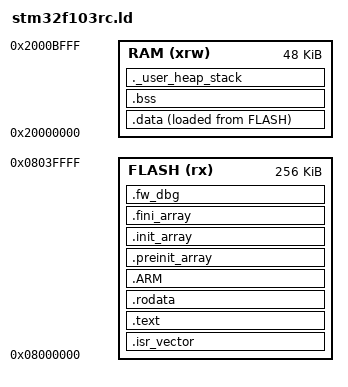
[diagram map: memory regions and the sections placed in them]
/*
 *
 * Automatically generated file
 * PlatformIO default linker script template for STM32 F1/F2/F3/F4/F7/L0/L1/L4
 *
 */

/* Entry Point */
ENTRY(Reset_Handler)

/* Highest address of the user mode stack */ 
_estack = 0x2000c000;    /* end of RAM */
/* Generate a link error if heap and stack don't fit into RAM */
_Min_Heap_Size = 0x8400;      /* required amount of heap  */
_Min_Stack_Size = 0x1600;     /* required amount of stack */

__stack_limit = _estack - _Min_Stack_Size;  /* end of stack */

/* Specify the memory areas */
MEMORY
{
    RAM (xrw)      : ORIGIN = 0x20000000, LENGTH = 49152
    FLASH (rx)      : ORIGIN = 0x8000000, LENGTH = 256K
}

/* Define output sections */
SECTIONS
{
  /* The startup code goes first into FLASH */
  .isr_vector :
  {
    . = ALIGN(4);
    KEEP(*(.isr_vector)) /* Startup code */
    . = ALIGN(4);
  } >FLASH

  /* The program code and other data goes into FLASH */
  .text :
  {
    . = ALIGN(4);
    *(.text)           /* .text sections (code) */
    *(.text*)          /* .text* sections (code) */
    *(.glue_7)         /* glue arm to thumb code */
    *(.glue_7t)        /* glue thumb to arm code */
    *(.eh_frame)

    KEEP (*(.init))
    KEEP (*(.fini))

    . = ALIGN(4);
    _etext = .;        /* define a global symbols at end of code */
  } >FLASH

  /* Constant data goes into FLASH */
  .rodata :
  {
    . = ALIGN(4);
    *(.rodata)         /* .rodata sections (constants, strings, etc.) */
    *(.rodata*)        /* .rodata* sections (constants, strings, etc.) */
    . = ALIGN(4);
  } >FLASH

  .ARM : {
    __exidx_start = .;
    __exidx_end = .;
  } >FLASH   /* we provide our own exception handling stuff */

  .preinit_array     :
  {
    PROVIDE_HIDDEN (__preinit_array_start = .);
    KEEP (*(.preinit_array*))
    PROVIDE_HIDDEN (__preinit_array_end = .);
  } >FLASH
  .init_array :
  {
    PROVIDE_HIDDEN (__init_array_start = .);
    KEEP (*(SORT(.init_array.*)))
    KEEP (*(.init_array*))
    PROVIDE_HIDDEN (__init_array_end = .);
  } >FLASH
  .fini_array :
  {
    PROVIDE_HIDDEN (__fini_array_start = .);
    KEEP (*(SORT(.fini_array.*)))
    KEEP (*(.fini_array*))
    PROVIDE_HIDDEN (__fini_array_end = .);
  } >FLASH

  /* used by the startup to initialize data */
  _sidata = LOADADDR(.data);

  /* Initialized data sections goes into RAM, load LMA copy after code */
  .data : 
  {
    . = ALIGN(4);
    _sdata = .;        /* create a global symbol at data start */
    *(.data)           /* .data sections */
    *(.data*)          /* .data* sections */

    . = ALIGN(4);
    _edata = .;        /* define a global symbol at data end */
  } >RAM AT> FLASH
  
  /* Uninitialized data section */
  . = ALIGN(4);
  .bss :
  {
    /* This is used by the startup in order to initialize the .bss secion */
    _sbss = .;         /* define a global symbol at bss start */
    __bss_start__ = _sbss;
    *(.bss)
    *(.bss*)
    *(COMMON)

    . = ALIGN(4);
    _ebss = .;         /* define a global symbol at bss end */
    __bss_end__ = _ebss;
  } >RAM

  /* User_heap_stack section, used to check that there is enough RAM left */
  ._user_heap_stack :
  {
    . = ALIGN(4);
    PROVIDE ( end = . );
    PROVIDE ( _end = . );
    . = . + _Min_Heap_Size;
    . = . + _Min_Stack_Size;
    . = ALIGN(4);
  } >RAM

  /* DEBUG REGION */
  .fw_dbg :
  {
	  . = ALIGN(4);  /* align to word access */
	  PROVIDE (dbg_symtable_size = .);  /* provide place to store size of symbol table, as unwind table is after it */
	  PROVIDE (_dbg_symtable_size = .);
	  . = . + 4; /*  go past it */
	  PROVIDE (dbg_data_begin = .);  /* binary data will now be placed here */
	  PROVIDE (_dbg_data_begin = .);
  } >FLASH

  /* Remove information from the standard libraries */
  /DISCARD/ :
  {
    libc.a ( * )
    libm.a ( * )
    libgcc.a ( * )
	*(.ARM.ex*)
  }

  .ARM.attributes 0 : { *(.ARM.attributes) }
}


